# AU301LDF51 register map
File version: 1.0
Registers are 32-bit, access per field, reset 0x0 unless marked. A register's access mark holds for its fields unless they carry their own. Offsets are from the block's base; [hi:lo] are bit positions; {n}, {i} and the like mark numbered series.

## SYSCTRL1 — SYSCTRL1_REG peripheral interface
Base 0x10100000
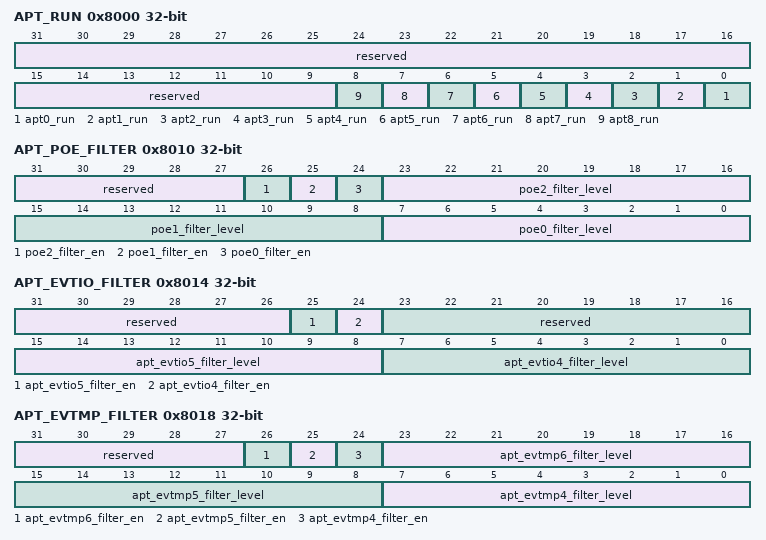
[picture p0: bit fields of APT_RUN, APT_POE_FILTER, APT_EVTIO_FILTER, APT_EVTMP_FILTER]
0x8000 APT_RUN — APT使能控制寄存器。
  [31:9] reserved ro — 保留。
  [n] apt{n}_run rw (n=0..8) — APT{n}使能。 1：使能； 0：不使能。
0x8010 APT_POE_FILTER — APT POE滤波控制寄存器。
  [31:27] reserved ro — 保留。
  [26] poe2_filter_en rw — POE2 FILTER使能。 0：不使能； 1：使能。
  [25] poe1_filter_en rw — POE1 FILTER使能。 0：不使能； 1：使能。
  [24] poe0_filter_en rw — POE0 FILTER使能。 0：不使能； 1：使能。
  [23:16] poe2_filter_level rw — POE2 FILTER周期数（clk_hs）。
  [15:8] poe1_filter_level rw — POE1 FILTER周期数（clk_hs）。
  [7:0] poe0_filter_level rw — POE0 FILTER周期数（clk_hs）。
0x8014 APT_EVTIO_FILTER — APT EVTIO滤波控制寄存器。
  [31:26] reserved ro — 保留。
  [25] apt_evtio5_filter_en rw — APT EVTIO5 FILTER使能。 0：不使能； 1：使能。
  [24] apt_evtio4_filter_en rw — APT EVTIO4 FILTER使能。 0：不使能； 1：使能。
  [23:16] reserved ro — 保留。
  [15:8] apt_evtio5_filter_level rw — APT EVTIO5 FILTER周期数（clk_hs）。
  [7:0] apt_evtio4_filter_level rw — APT EVTIO4 FILTER周期数（clk_hs）。
0x8018 APT_EVTMP_FILTER — APT EVTMP滤波控制寄存器。
  [31:27] reserved ro — 保留。
  [26] apt_evtmp6_filter_en rw — APT EVTMP6 FILTER使能。 0：不使能； 1：使能。
  [25] apt_evtmp5_filter_en rw — APT EVTMP5 FILTER使能。 0：不使能； 1：使能。
  [24] apt_evtmp4_filter_en rw — APT EVTMP4 FILTER使能。 0：不使能； 1：使能。
  [23:16] apt_evtmp6_filter_level rw — APT EVTMP6 FILTER周期数（clk_hs）。
  [15:8] apt_evtmp5_filter_level rw — APT EVTMP5 FILTER周期数（clk_hs）。
  [7:0] apt_evtmp4_filter_level rw — APT EVTMP4 FILTER周期数（clk_hs）。
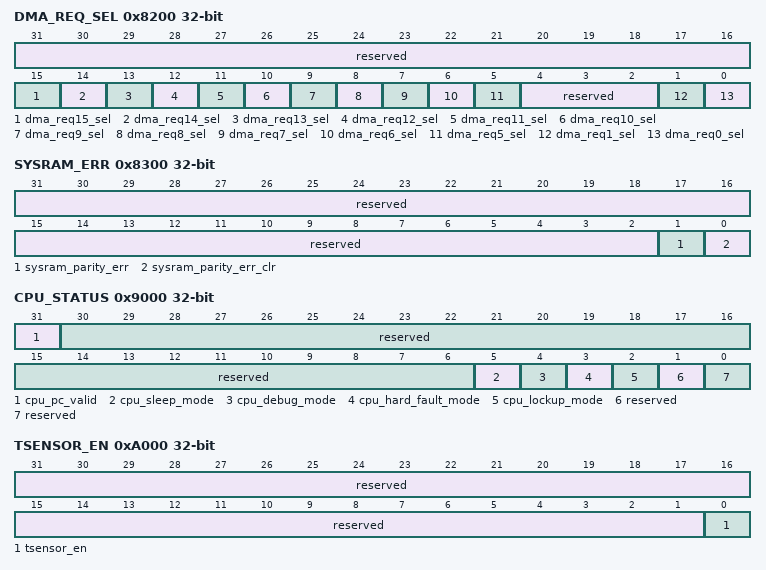
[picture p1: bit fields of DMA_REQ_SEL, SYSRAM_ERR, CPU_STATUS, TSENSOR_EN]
0x8200 DMA_REQ_SEL — DMA请求线源选择寄存器。
  [31:16] reserved ro — 保留。
  [15] dma_req15_sel rw — DMA请求线15源选择。 0：TIMER1； 1：APT7。
  [14] dma_req14_sel rw — DMA请求线14源选择。 0：TIMER0； 1：APT6。
  [13] dma_req13_sel rw — DMA请求线13源选择。 0：ADC2； 1：APT5。
  [12] dma_req12_sel rw — DMA请求线12源选择。 0：ADC1； 1：APT4。
  [11] dma_req11_sel rw — DMA请求线11源选择。 0：ADC0； 1：APT3。
  [10] dma_req10_sel rw — DMA请求线10源选择。 0：CAPM2； 1：APT2。
  [9] dma_req9_sel rw — DMA请求线9源选择。 0：CAPM1； 1：APT1。
  [8] dma_req8_sel rw — DMA请求线8源选择。 0：CAPM0； 1：APT0。
  [7] dma_req7_sel rw — DMA请求线7源选择。 0：UART2_TX； 1：SPI_TX；
  [6] dma_req6_sel rw — DMA请求线6源选择。 0：UART2_RX； 1：SPI_RX。
  [5] dma_req5_sel rw — DMA请求线5源选择。 0：UART1_TX； 1：APT8。
  [4:2] reserved ro — 保留。
  [1] dma_req1_sel rw — DMA请求线1源选择。 0：I2C_TX； 1：TIMER3。
  [0] dma_req0_sel rw — DMA请求线0源选择。 0：I2C_RX； 1：TIMER2。
0x8300 SYSRAM_ERR — SYSRAM奇偶校验状态寄存器。
  [31:2] reserved ro — 保留。
  [1] sysram_parity_err ro — SYSRAM奇偶校验错误状态。 0：无错误； 1：有错误。
  [0] sysram_parity_err_clr wo — SYSRAM奇偶校验错误状态清除。 向该位域执行写动作，会清除SYSRAM奇偶校验错误状态。
0x9000 CPU_STATUS ro — CPU状态寄存器。
  [31] cpu_pc_valid — CPU PC值有效状态。 0：PC值无效； 1：PC值有效。
  [30:6] reserved — 保留。
  [5] cpu_sleep_mode — CPU SLEEP状态。 0：非sleep状态； 1：sleep状态。
  [4] cpu_debug_mode — CPU DEBUG状态。 0：非debug状态； 1：debug状态。
  [3] cpu_hard_fault_mode — CPU HARD FAULT状态。 0：非hard_fault状态； 1：hard_fault状态。
  [2] cpu_lockup_mode — CPU LOCKUP状态。 0：非lockup状态； 1：lockup状态。
  [1] reserved
  [0] reserved
0xA000 TSENSOR_EN — Tsensor使能控制寄存器。
  [31:1] reserved ro — 保留。
  [0] tsensor_en rw — Tsensor使能。 0：不使能； 1：使能。
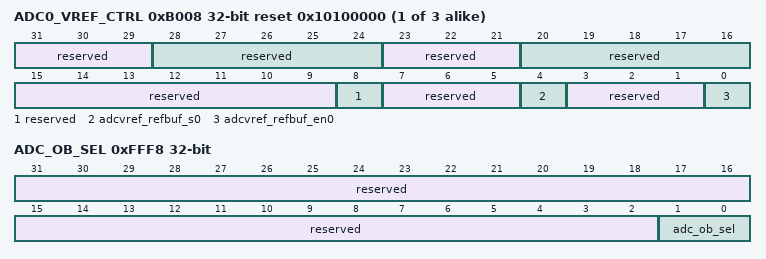
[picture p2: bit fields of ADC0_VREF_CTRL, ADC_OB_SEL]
{0xB008+4i} ADC{i}_VREF_CTRL reset 0x10100000 (i=0..2) — ADC{i} VREF控制寄存器。
  [31:29] reserved ro — 保留。
  [28:24] reserved rw
  [23:21] reserved ro
  [20:16] reserved rw
  [15:9] reserved ro
  [8] reserved rw
  [7:5] reserved ro
  [4] adcvref_refbuf_s{i} rw — ADC{i} VREF电压选择。 0：ADC{i} VREF = 2.0V； 1：ADC{i} VREF = 2.5V。
  [3:1] reserved ro — 保留。
  [0] adcvref_refbuf_en{i} rw — ADC{i} VREF使能。 0：不使能； 1：使能。
0xFFF8 ADC_OB_SEL — ADC串行观测选择寄存器。
  [31:2] reserved ro — 保留。
  [1:0] adc_ob_sel rw — ADC串行输出观测选择。 0：ADC0； 1：ADC1； 2：ADC2； 3：保留。

## TIMER0 — TIMER peripheral interface
Base 0x14300000
Same registers: TIMER1 0x14300020, TIMER2 0x14301000
0x00 TIMERx_LOAD rw — 计数初值寄存器
  [31:0] timer_load — Timer的计数初值
0x04 TIMERx_VALUE ro reset 0xFFFFFFFF — 当前计数值寄存器
  [31:0] timer_value — 正在递减的Timer的当前值
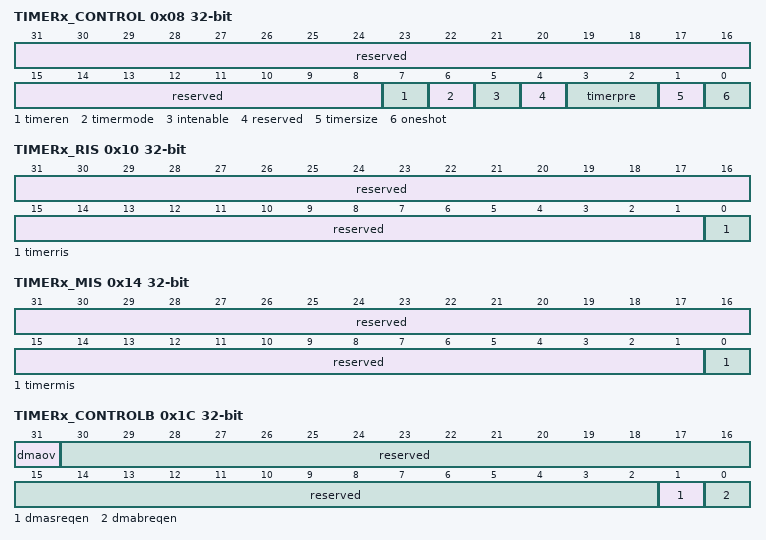
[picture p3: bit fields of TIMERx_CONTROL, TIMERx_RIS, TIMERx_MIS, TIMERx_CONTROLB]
0x08 TIMERx_CONTROL — Timer控制寄存器
  [31:8] reserved ro — 保留。
  [7] timeren rw — 定时器使能。 0：Timer禁止； 1：Timer使能。
  [6] timermode rw — 定时器的计数模式。 0：自由运行模式； 1：周期模式。
  [5] intenable rw — TIMERx_RIS中断屏蔽。 0：屏蔽该中断； 1：不屏蔽该中断。
  [4] reserved ro — 保留。
  [3:2] timerpre rw — 该字段用于设置timer的预分频因子。 00：不经过预分频，时钟频率除以1； 01：4级预分频，将timer时钟频率除以16； 10：8级预分频，将timer时钟频率除以256； 11：未定义，若设为该值，相当于8级预分频，将timer时钟频率除以256；
  [1] timersize rw — 选择16bit/32bit计数器操作模式。 0：16bit计数器； 1：32bit计数器。
  [0] oneshot rw — 选择计数模式为单次计数模式还是周期计数模式。 0：周期计数模式或自由运行模式； 1：单次计数模式。
0x0C TIMERx_INTCLR wo — 中断清除寄存器
  [31:0] timer_intclr — 写该寄存器，清除timer的中断输出。
0x10 TIMERx_RIS ro — 原始中断寄存器
  [31:1] reserved — 保留。写入无效，读时返回0。
  [0] timerris — timer的原始中断状态。 0：未产生中断； 1：已产生中断。
0x14 TIMERx_MIS ro — 屏蔽后中断寄存器
  [31:1] reserved — 保留。
  [0] timermis — 屏蔽后的timer的中断状态。 0：中断无效； 1：中断有效。
0x18 TIMERx_BGLOAD rw — 周期模式计数初值寄存器
  [31:0] timerbgload — timer的计数初值。 注意：与 TIMERx_LOAD 寄存器有区别，具体请参见 TIMERx_LOAD 寄存器的描 述。
0x1C TIMERx_CONTROLB — TIMER 的 DMA/ADC 控制寄存器。
  [31] dmaov rw write-1-clears — DMA请求溢出标志。 读出0：无DMA请求溢出； 读出1：产生DMA请求溢出； 写入0：无影响； 写入1：清除溢出标志。
  [30:2] reserved ro — 保留。
  [1] dmasreqen rw — DMA Single请求和触发ADC采样的使能位。 0：禁止产生DMA Single 请求，并禁止产生触发ADC采样的信号（SOC信号）； 1：可以产生DMA Single请求，并可以产生触发ADC采样的信号（SOC信号）。
  [0] dmabreqen rw — DMA Burst 请求使能位。 0：禁止产生DMA Burst 请求； 1：可以产生DMA Burst 请求。

## WDG
Base 0x14400000
Same registers: IWDG 0x14401000
0x00 WDG_LOAD rw reset 0xFFFFFFFF — 计数初值寄存器。用来配置 WatchDog 内部计数器的计数初值。
  [31:0] wdg_load — 计数初值。当 WatchDog 正在运行时向此寄存器写入数据，计数器马上从新值开始重新计数。 WatchDog 加载此寄存器的值还可以通过： 计数值递减到 0； 重新使能 WDG_CONTROL[wdgen]信号； 写入 WDG_INTCLR 清除中断。
0x04 WDG_VALUE ro reset 0xFFFFFFFF — 计数器当前值寄存器。用来读出 WatchDog 内部计数器的当前计数值。
  [31:0] wdogvalue — WatchDog 计数器当前值。
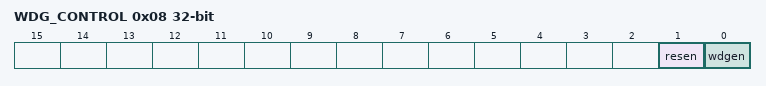
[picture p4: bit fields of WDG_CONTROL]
0x08 WDG_CONTROL — 为控制寄存器。用来控制 WatchDog 的打开/关闭、中断和复位功能。
  [1] resen rw — WatchDog 复位信号输出使能。 0：禁止； 1：使能。
  [0] wdgen rw — WatchDog 使能。 0：计数器停止计数，计数值保持当前值不变，WatchDog 被关闭； 1：既启动计数器又使能中断，WatchDog被启动。
0x0C WDG_INTCLR rw — 中断清除寄存器。用来清除 WatchDog 中断，使 WatchDog 重新载入初值进行计数。本寄存器是只写寄存器，写进去任意值，都会引起 WatchDog 清中断，内部并不记忆写入的值，无复位值。
  [31:0] wdg_intclr — 对该寄存器写入任意值均可清除 WatchDog 的中断，并使 WatchDog 从寄存器 WDG_LOAD 中重新载入初值计数。
0x10 WDG_RIS ro — 原始中断寄存器。用来反映 WatchDog 原始中断状态。
  [0] wdogris — WatchDog 原始中断状态，当计数器的计数值递减到 0 时，该位置 1。 0：未产生中断； 1：已产生中断。
0x14 WDG_MIS ro — 屏蔽后中断寄存器。用来反映屏蔽后的 WatchDog 中断状态。
  [0] wdogmis — WatchDog 屏蔽后的中断状态。 0：未产生中断或者中断被屏蔽； 1：已产生中断。
0xC00 WDG_LOCK rw — LOCK 寄存器。用来控制 WatchDog 寄存器的写权限。在芯片上电或复位后，WDG_LOCK 默认为打开所有寄存器写权限的状态，此时可以对所有寄存器进行写入。
  [31:0] wdg_lock — 向该寄存器写入 0x1ACC_E551，可打开所有寄存器的写权限； 向该寄存器写入其他值则关闭写权限。 读该寄存器返回加锁的状态而不是写入该寄存器的值： 0x0000_0000：允许写访问（未加锁）； 0x0000_0001：禁止写访问（已加锁）。
